# f29h85x_hsm_aes_p_regs register map
Vendor: Texas Instruments
Peripheral module from a debugger description file (folder HSM).
Registers are 32-bit, read-write, no defined reset value unless marked. A register's access mark holds for its fields unless they carry their own. Offsets are as the file gives them; lines under a group give offsets from that group; [hi:lo] are bit positions; {n}, {i} and the like mark numbered series; 'fields as' and 'values as' point back to an identical list; <NAME> marks a mode.

## HSM_AES_P — HSM AES P Registers
0x00 P_KEY2_6
  [31:0] KEY
0x04 P_KEY2_7
  [31:0] KEY
0x08 P_KEY2_4
  [31:0] KEY
0x0C P_KEY2_5
  [31:0] KEY
0x10 P_KEY2_2
  [31:0] KEY
0x14 P_KEY2_3
  [31:0] KEY
0x18 P_KEY2_0
  [31:0] KEY
0x1C P_KEY2_1
  [31:0] KEY
0x20 P_KEY1_6
  [31:0] KEY
0x24 P_KEY1_7
  [31:0] KEY
0x28 P_KEY1_4
  [31:0] KEY
0x2C P_KEY1_5
  [31:0] KEY
0x30 P_KEY1_2
  [31:0] KEY
0x34 P_KEY1_3
  [31:0] KEY
0x38 P_KEY1_0
  [31:0] KEY
0x3C P_KEY1_1
  [31:0] KEY
{0x40+4i} P_IV_IN_{i} (i=0..3)
  [31:0] DATA
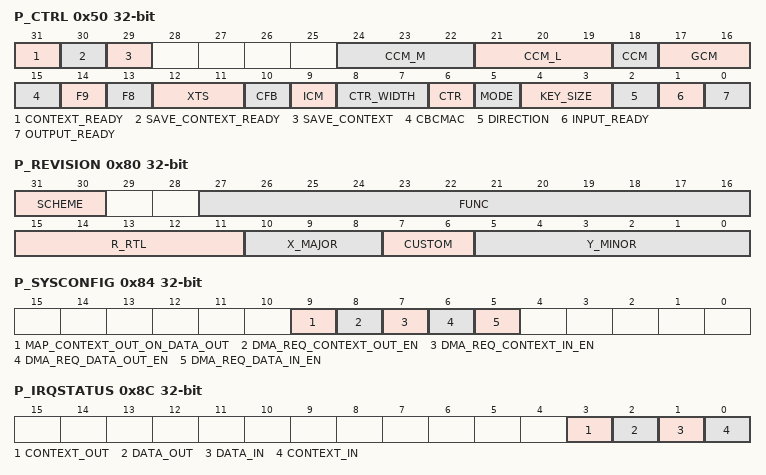
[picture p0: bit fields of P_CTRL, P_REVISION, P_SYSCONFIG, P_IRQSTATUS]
0x50 P_CTRL access per field
  [31] CONTEXT_READY ro, [30] SAVE_CONTEXT_READY ro, [29] SAVE_CONTEXT rw, [24:22] CCM_M rw, [21:19] CCM_L rw, [18] CCM rw, [17:16] GCM rw, [15] CBCMAC rw, [14] F9 rw, [13] F8 rw, [12:11] XTS rw, [10] CFB rw, [9] ICM rw, [8:7] CTR_WIDTH rw, [6] CTR rw, [5] MODE rw, [4:3] KEY_SIZE rw, [2] DIRECTION rw, [1] INPUT_READY ro, [0] OUTPUT_READY ro
0x54 P_C_LENGTH_0
  [31:0] LENGTH
0x58 P_C_LENGTH_1 access per field
  [28:0] LENGTH rw
0x5C P_AUTH_LENGTH
  [31:0] AUTH
{0x60+4i} P_DATA_IN_OUT_{i} (i=0..3)
  [31:0] DATA
{0x70+4i} P_TAG_OUT_{i} ro (i=0..3)
  [31:0] HASH
0x80 P_REVISION ro
  [31:30] SCHEME, [27:16] FUNC, [15:11] R_RTL, [10:8] X_MAJOR, [7:6] CUSTOM, [5:0] Y_MINOR
0x84 P_SYSCONFIG access per field
  [9] MAP_CONTEXT_OUT_ON_DATA_OUT rw, [8] DMA_REQ_CONTEXT_OUT_EN rw, [7] DMA_REQ_CONTEXT_IN_EN rw, [6] DMA_REQ_DATA_OUT_EN rw, [5] DMA_REQ_DATA_IN_EN rw
0x88 P_SYSSTATUS ro
  [0] RESETDONE
0x8C P_IRQSTATUS access per field
  [3] CONTEXT_OUT rw, [2] DATA_OUT rw, [1] DATA_IN rw, [0] CONTEXT_IN rw
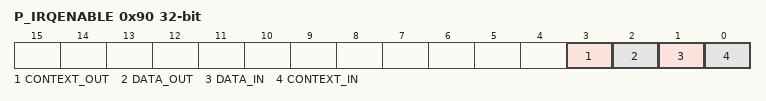
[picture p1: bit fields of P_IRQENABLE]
0x90 P_IRQENABLE access per field
  fields as P_IRQSTATUS
